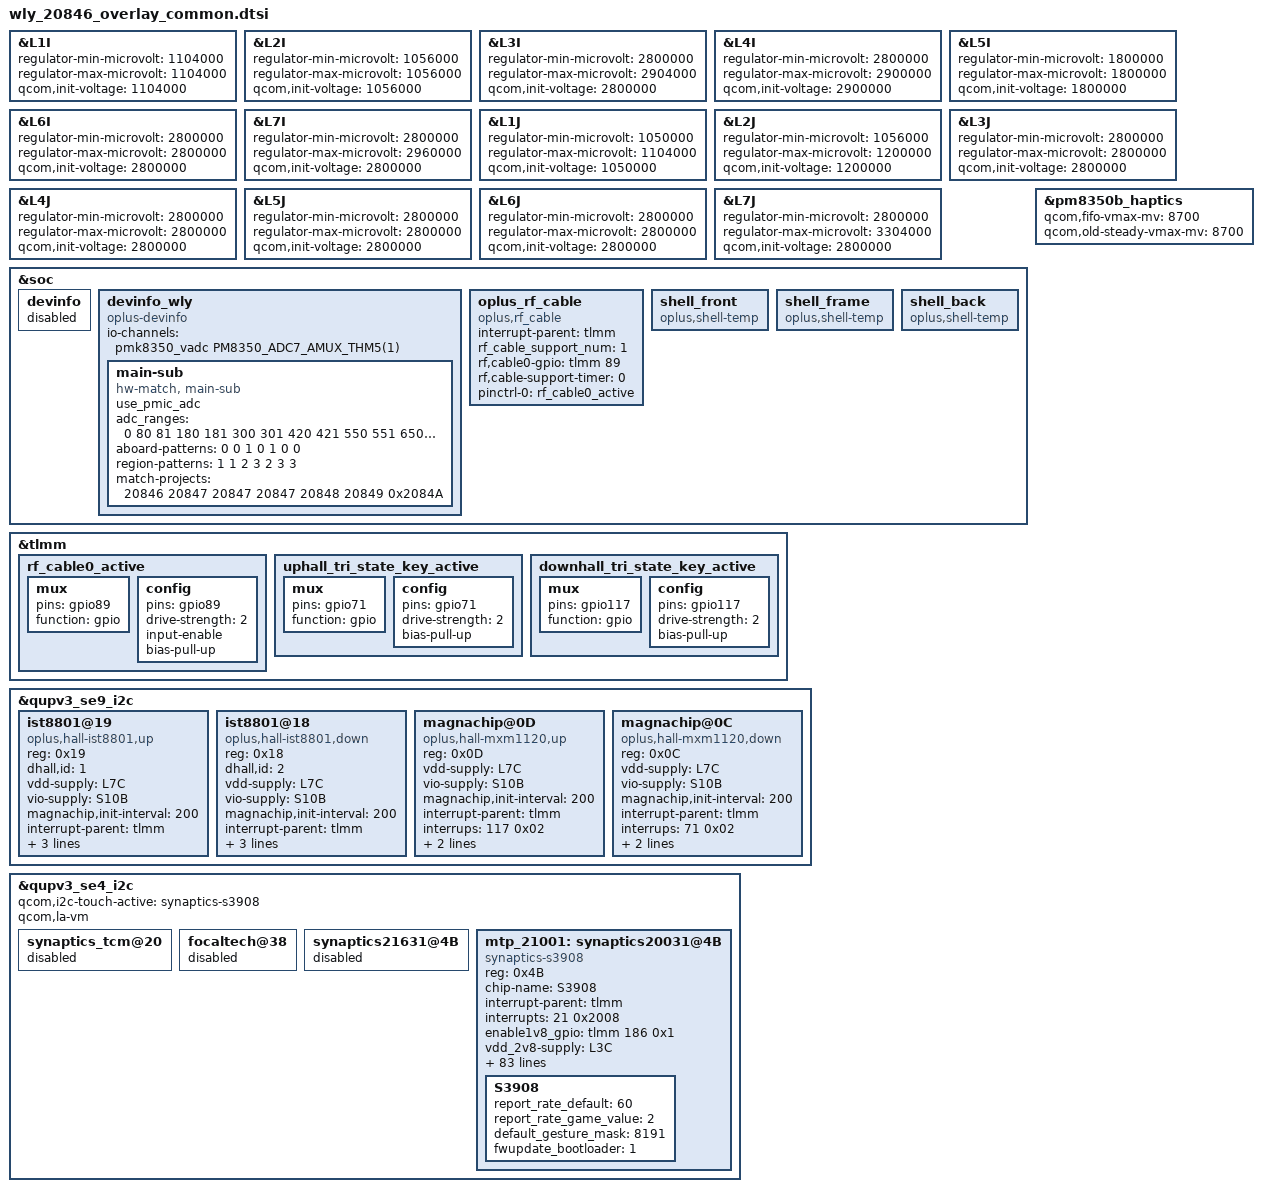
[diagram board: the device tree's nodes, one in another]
/* Waipio configurations for PM8010I and PM8010J connected via SPMI */
&L1I {
    regulator-min-microvolt = <1104000>;
    regulator-max-microvolt = <1104000>;
    qcom,init-voltage = <1104000>;
};

&L2I{
    regulator-min-microvolt = <1056000>;
    regulator-max-microvolt = <1056000>;
    qcom,init-voltage = <1056000>;
};

&L3I{
    regulator-min-microvolt = <2800000>;
    regulator-max-microvolt = <2904000>;
    qcom,init-voltage = <2800000>;
};

&L4I{
    regulator-min-microvolt = <2800000>;
    regulator-max-microvolt = <2900000>;
    qcom,init-voltage = <2900000>;
};

&L5I{
    regulator-min-microvolt = <1800000>;
    regulator-max-microvolt = <1800000>;
    qcom,init-voltage = <1800000>;
};

&L6I{
    regulator-min-microvolt = <2800000>;
    regulator-max-microvolt = <2800000>;
    qcom,init-voltage = <2800000>;
};

&L7I{
    regulator-min-microvolt = <2800000>;
    regulator-max-microvolt = <2960000>;
    qcom,init-voltage = <2800000>;
};

&L1J{
    regulator-min-microvolt = <1050000>;
    regulator-max-microvolt = <1104000>;
    qcom,init-voltage = <1050000>;
};

&L2J{
    regulator-min-microvolt = <1056000>;
    regulator-max-microvolt = <1200000>;
    qcom,init-voltage = <1200000>;
};

&L3J{
    regulator-min-microvolt = <2800000>;
    regulator-max-microvolt = <2800000>;
    qcom,init-voltage = <2800000>;
};

&L4J{
    regulator-min-microvolt = <2800000>;
    regulator-max-microvolt = <2800000>;
    qcom,init-voltage = <2800000>;
};

&L5J{
    regulator-min-microvolt = <2800000>;
    regulator-max-microvolt = <2800000>;
    qcom,init-voltage = <2800000>;
};

&L6J{
    regulator-min-microvolt = <2800000>;
    regulator-max-microvolt = <2800000>;
    qcom,init-voltage = <2800000>;
};

&L7J{
    regulator-min-microvolt = <2800000>;
    regulator-max-microvolt = <3304000>;
    qcom,init-voltage = <2800000>;
};

&soc {
    devinfo {
        status = "disabled";
    };

	devinfo_wly {
		compatible = "oplus-devinfo";

		//pinctrl-names = "active", "sleep";
		//pinctrl-0 = <&hw_id_active>;
		//pinctrl-1 = <&hw_id_sleep>;

		io-channels= <&pmk8350_vadc PM8350_ADC7_AMUX_THM5(1)>;
		io-channel-names= "vph_pwr_voltage_sub";

		main-sub {
			compatible = "hw-match, main-sub";
			use_pmic_adc;
			adc_ranges = <0 80
					81 180
					181 300
					301 420
					421 550
					551 650
					651 760
					761 850
					851 950
					951 1050
					1051 1150
					1151 1300>;
			aboard-patterns = <0 0 1 0 1 0 0>;
			region-patterns = <1 1 2 3 2 3 3>;

			/*main board*/
			match-projects = <20846 20847 20847 20847 20848 20849 0x2084A>;

		};
	};
};

//#ifdef OPLUS_FEATURE_RF_CABLE_DETECT
&tlmm {
  rf_cable0_active: rf_cable0_active {
    mux {
      pins = "gpio89";
      function = "gpio";
    };
    config {
      pins = "gpio89";
      drive-strength = <2>;
      input-enable;
      bias-pull-up;
    };
  };
};

&soc {
  oplus_rf_cable {
    compatible = "oplus,rf_cable";
    interrupt-parent = <&tlmm>;
    rf_cable_support_num = <1>;
    rf,cable0-gpio = <&tlmm 89 0>;
    rf,cable-support-timer = <0>;
    pinctrl-names = "rf_cable_active";
    pinctrl-0 = <&rf_cable0_active>;
  };
};
//#endif /* OPLUS_FEATURE_RF_CABLE_DETECT */

&soc {
	//#ifdef OPLUS_FEATURE_THERMAL_HORAE
		shell_front {
				compatible = "oplus,shell-temp";
		};

		shell_frame {
				compatible = "oplus,shell-temp";
		};

		shell_back {
				compatible = "oplus,shell-temp";
		};
	//#endif
};

//#ifdef OPLUS_FEATURE_CHG_BASIC
&pm8350b_haptics {
    qcom,fifo-vmax-mv = <8700>;
    qcom,old-steady-vmax-mv = <8700>;//8.7v
};
//#endif

&tlmm {
	uphall_tri_state_key_active: uphall_tri_state_key_active {
		mux {
			pins = "gpio71";
			function = "gpio";
		};
		config {
			pins = "gpio71";
			drive-strength = <2>;
			bias-pull-up;
		};
	};
	downhall_tri_state_key_active: downhall_tri_state_key_active {
		mux {
			pins = "gpio117";
			function = "gpio";
		};
		config {
			pins = "gpio117";
			drive-strength = <2>;
			bias-pull-up;
		};
	};
};

&qupv3_se9_i2c {
	ist8801@19 {
		compatible = "oplus,hall-ist8801,up";
		reg = <0x19>;
		dhall,id = <1>;
		vdd-supply = <&L7C>;
		vio-supply = <&S10B>;
		magnachip,init-interval = <200>;
		interrupt-parent = <&tlmm>;
		interrups = <117 0x02>;
		dhall,irq-gpio = <&tlmm 117 0x2008>;
		pinctrl-names = "uphall_tri_state_key_active";
		pinctrl-0 = <&uphall_tri_state_key_active>;
	};
	ist8801@18 {
		compatible = "oplus,hall-ist8801,down";
		reg = <0x18>;
		dhall,id = <2>;
		vdd-supply = <&L7C>;
		vio-supply = <&S10B>;
		magnachip,init-interval = <200>;
		interrupt-parent = <&tlmm>;
		interrups = <71 0x02>;
		dhall,irq-gpio = <&tlmm 71 0x2008>;
		pinctrl-names = "downhall_tri_state_key_active";
		pinctrl-0 = <&downhall_tri_state_key_active>;
	};

	magnachip@0D {
		compatible = "oplus,hall-mxm1120,up";
		reg = <0x0D>;
		vdd-supply = <&L7C>;
		vio-supply = <&S10B>;
		magnachip,init-interval = <200>;
		interrupt-parent = <&tlmm>;
		interrups = <117 0x02>;
		dhall,irq-gpio = <&tlmm 117 0x2008>;
		pinctrl-names = "uphall_tri_state_key_active";
		pinctrl-0 = <&uphall_tri_state_key_active>;
	};
	magnachip@0C {
		compatible = "oplus,hall-mxm1120,down";
		reg = <0x0C>;
		vdd-supply = <&L7C>;
		vio-supply = <&S10B>;
		magnachip,init-interval = <200>;
		interrupt-parent = <&tlmm>;
		interrups = <71 0x02>;
		dhall,irq-gpio = <&tlmm 71 0x2008>;
		pinctrl-names = "downhall_tri_state_key_active";
		pinctrl-0 = <&downhall_tri_state_key_active>;
	};
//#endif /*OPLUS_FEATURE_TP_BASIC*/
};

&qupv3_se4_i2c {
	qcom,i2c-touch-active = "synaptics-s3908";
	qcom,la-vm;

	synaptics_tcm@20 {
		status = "disabled";
	};

	focaltech@38 {
		status = "disabled";
	};

	synaptics21631@4B {
		status = "disabled";
	};

	mtp_21001:synaptics20031@4B {
		compatible = "synaptics-s3908";
		reg = <0x4B>;
		chip-name = "S3908";

		/* Interrupt && Irq-gpio */
		interrupt-parent = <&tlmm>;
		interrupts = <21 0x2008>;

		/* Power Config */
		//enable2v8_gpio = <&tlmm 26 0x1>;
		enable1v8_gpio = <&tlmm 97 0x1>;
		vdd_2v8-supply = <&L3C>;
		vcc_1v8-supply = <&L4H>;
		vdd_2v8_volt = <3008000>;

		/* Other HW Resource */
		irq-gpio = <&tlmm 21 0x2008>;
		reset-gpio = <&tlmm 20 0x1>;
		pinctrl-names = "default";
		pinctrl-0 = <&ts_int_active &ts_reset_active>;

		touchpanel,max-num-support = <10>;
		touchpanel,tx-rx-num = <17 38>;
		earsense,tx-rx-num = <17 18>;
		touchpanel,panel-coords = <5760 12864>;
		touchpanel,display-coords = <1440 3216>;
		touchpanel,touchmajor-limit = <256 256>;
		touchpanel,int-mode = <1>; /*0: interrupt and disable, 1:interrupt and not disable*/
		touchpanel,curved-size = <45>;

		prevention,curved_screen_V2;
		prevention,grip_disable_level = <6>;
		prevention,updelay_time_ms = <30>;
		prevention,makeup_cnt_weight = <4 1 2 2 2>;
		prevention,large_corner_range = <600 1400>;
		prevention,large_corner_judge_condition = <500 100 600 4 4>;
		prevention,trx_reject_condition = <8 7 7>;
		prevention,trx_strict_reject_condition = <8 5 5>;
		prevention,large_judge_time_ms = <500 50 40>;
		prevention,large_exit_condition = <8 8 2>;
		prevention,single_channel_width = <160 160>;
		prevention,normal_tap_condition = <10 300>;
		prevention,long_edge_condition = <230 90 180 80>;
		prevention,long_strict_edge_condition = <160 60>;
		prevention,long_fingerhold_condition = <50 6 4 4>;
		prevention,short_edge_condition = <200 90 180 80>;
		prevention,short_strict_edge_condition = <160 60>;
		prevention,large_strict_exit_condition = <2 2>;
		prevention,top_corner_config = <280 800 240>;
		prevention,edge_swipe_config = <150 400>;

		touchpanel,smooth-level = <0 1 2 4 7 9>;
		touchpanel,smooth-level-charging = <0 2 4 7 8 9>;
		touchpanel,sensitive-level = <0 70 55 40 25 10>;
		touchpanel,single-optimized-time = <8>;
		touchpanel,high-frame-rate-time = <60>;

		end_stretch_value = <480 250 16 16>;

		touchpanel,tp_ic_type = <2>;
		panel_type = <8 8>;
		// type of tp_dev ,TP-SAMSUNG = 8;
		firmware_name = "SS";
		platform_support_project = <20031 21001 21201 20846 20847 20848 20849 0x2084A 21009>;
		platform_support_project_dir = <21001 21001 21001 21001 21001 21001 21001 21001 21009>;
		platform_support_project_commandline = "mdss_dsi_panel_samsung_amb670yf07_1440_3216_dsc_cmd","mdss_dsi_panel_samsung_amb670yf08_fs_1440_3216_dsc_cmd";

		/* SW Support Feature Control */
		exception_upload_support;
		black_gesture_support;
		sportify_aod_gesture_support;
		//fw_edge_limit_support;
		pressure_report_support;
		charger_pump_support;
		game_switch_support;
		smart_gesture_support;
		fw_update_app_support;
		fingerprint_underscreen_support;
		freq_hop_simulate_support;
		report_flow_unlock_support;
		screenoff_fingerprint_info_support;
		irq_need_dev_resume_ok;
		enable_point_auto_change;
		report_rate_white_list_support;
		kernel_grip_support;
		//grip_no_driver_support;
		health_monitor_support;
		black_gesture_indep_support;
		//algorithm_support;
		snr_read_support;
		//enable_touch_helper;
		trusted_touch_support;

		touchpanel,trusted-touch-mode = "vm_mode";
		touchpanel,touch-environment = "pvm";
		touchpanel,trusted-touch-type = "primary";
		touchpanel,trusted-touch-spi-irq = <754>;
		touchpanel,trusted-touch-io-bases = <0x990000 0x910000>;
		touchpanel,trusted-touch-io-sizes = <0x1000 0x4000>;
		touchpanel,trusted-touch-vm-gpio-list = <&tlmm 16 0 &tlmm 17 0 &tlmm 18 0
                                &tlmm 19 0 &tlmm 20 0 &tlmm 21 0x2008>;
		/*
		 *Virtual Key Config:
		 *1:touchpanel,button-type: <virtualkey_type  supportted_button-map>
		 *virtualkey_type:
		 *Type 1: using board_properties
		 *Type 2: using same IC (button zone&& touch zone are seprate)
		 *Type 3: using diffrent IC (button zone&& touch zone are seprate)
		 *Type 4: No need of virtual key process
		 *supportted_button-map:select|menu|home|back
		 *
		 *2:touchpanel,button-map
		 *type (X1,Y1)(X2,Y2)(X3,Y3)(Width_X,Hight_Y)--Only when button-type is 0
		 */
		touchpanel,button-type = <4>;
		touchpanel.button-TRx = <0 0>;

		S3908 {
			report_rate_default = <60>;
			report_rate_game_value = <2>;
			default_gesture_mask = <8191>;
			fwupdate_bootloader = <1>;
		};
	};
//#endif /*OPLUS_FEATURE_TP_BASIC*/
};

&mtp_21001 {
	vcc_1v8-supply = <&L6C>;
	enable1v8_gpio = <&tlmm 186 0x1>;
};

#include "tp/mtp21001-s3908-firmware.dtsi"
